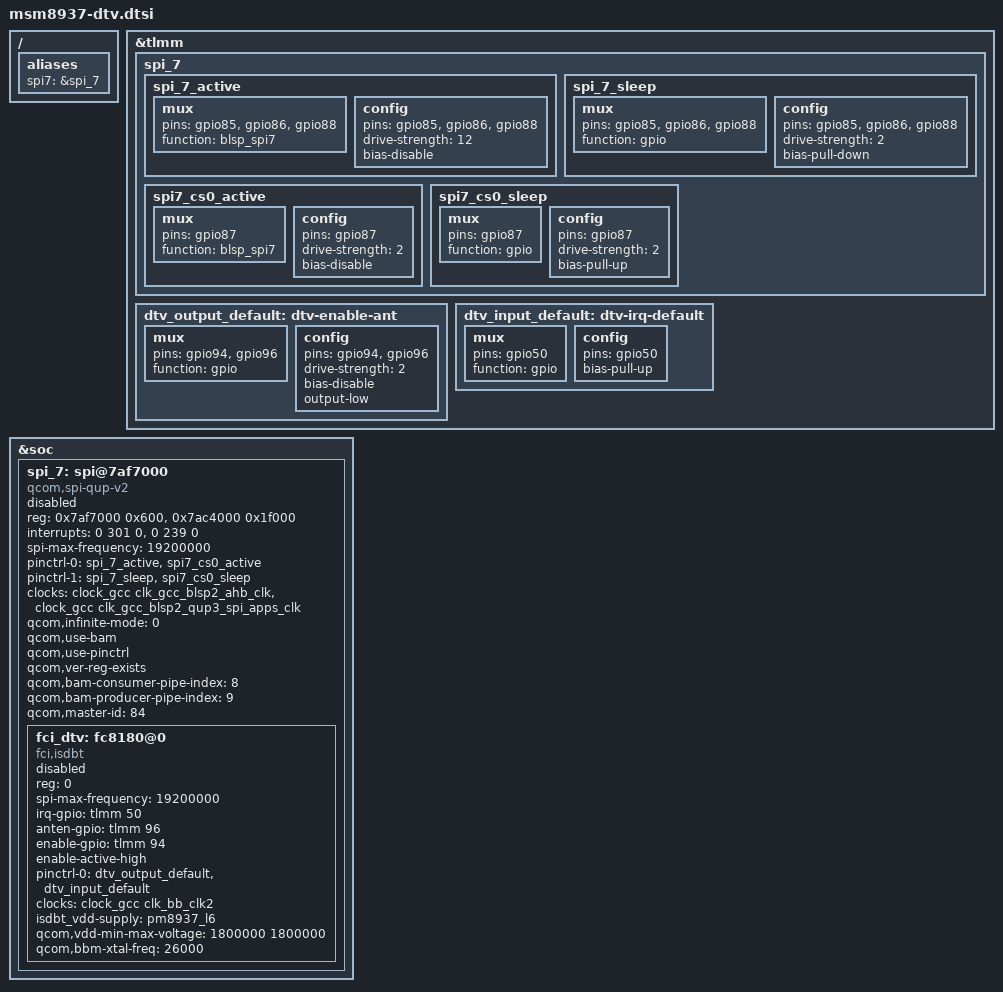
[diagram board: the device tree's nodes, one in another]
&tlmm {
	/delete-node/ spi7;
	spi_7 {
		/* BLSP7 MOSI, MISO, CLK */
		spi_7_active: spi_7_active {
			/* active state */
			mux {
				/* MOSI, MISO, CLK */
				pins = "gpio85", "gpio86", "gpio88";
				function = "blsp_spi7";
			};
			config {
				pins = "gpio85", "gpio86", "gpio88";
				drive-strength = <12>; /* 12 MA */
				bias-disable; /* No PULL */
			};
		};

		spi_7_sleep:spi_7_sleep {
			mux {
				/* MOSI, MISO, CLK */
				pins = "gpio85", "gpio86", "gpio88";
				function = "gpio";
			};
			config {
				pins = "gpio85", "gpio86", "gpio88";
				drive-strength = <2>; /* 2 MA */
				bias-pull-down; /* PULL Down */
			};
		};

		spi7_cs0_active: spi7_cs0_active {
			/* CS */
			mux {
				pins = "gpio87";
				function = "blsp_spi7";
			};
			config {
				pins = "gpio87";
				drive-strength = <2>;
				bias-disable;
			};
		};

		spi7_cs0_sleep: spi7_cs0_sleep {
			/* CS */
			mux {
				pins = "gpio87";
				function = "gpio";
			};
			config {
				pins = "gpio87";
				drive-strength = <2>;
				bias-pull-up;
			};
		};
	};

	/* DTV ldo enable and ant Switch pin */
	dtv_output_default: dtv-enable-ant {
		mux {
			/* enable, reset */
			pins = "gpio94", "gpio96";
			function = "gpio";
		};
		config {
			pins = "gpio94", "gpio96";
			drive-strength = <2>; /* 2 MA */
			bias-disable ; /* No PULL */
			output-low;
		};
	};
	/* DTV interrupt pin */
	dtv_input_default: dtv-irq-default {
			mux {
				pins = "gpio50";
				function = "gpio";
			};
			config {
				pins = "gpio50";
				bias-pull-up; /* pull up */
			};
	};
};

/ {
	aliases {
		spi7 = &spi_7;
    };
};

&soc {
	spi_7: spi@7af7000 { /* BLSP2 QUP2 */
		compatible = "qcom,spi-qup-v2";
		#address-cells = <1>;
		#size-cells = <0>;
		reg-names = "spi_physical", "spi_bam_physical";
		reg = <0x7af7000 0x600>,
		       <0x7ac4000 0x1f000>;
		interrupt-names = "spi_irq", "spi_bam_irq";
		/* IRQ 239 for BLSP2 */
		interrupts = <0 301 0>, <0 239 0>;
		spi-max-frequency = <19200000>;
		pinctrl-names = "spi_default", "spi_sleep";
		pinctrl-0 = <&spi_7_active &spi7_cs0_active>;
		pinctrl-1 = <&spi_7_sleep &spi7_cs0_sleep>;
		clocks = <&clock_gcc clk_gcc_blsp2_ahb_clk>,
			 <&clock_gcc clk_gcc_blsp2_qup3_spi_apps_clk>;
		clock-names = "iface_clk", "core_clk";
		qcom,infinite-mode = <0>;
		qcom,use-bam;
		qcom,use-pinctrl;
		qcom,ver-reg-exists;
		/* need to check pipe index setting*/
		qcom,bam-consumer-pipe-index = <8>;
		qcom,bam-producer-pipe-index = <9>;
		/* master-id for BLSP2 is MSM_BUS_MASTER_BLSP_2 or 84 */
		qcom,master-id = <84>;
		status = "/chosen", "mmi,dtv", "true";

		fci_dtv: fc8180@0 {
			status = "/chosen", "mmi,dtv", "true";
			compatible = "fci,isdbt";
			reg = <0>;
			spi-max-frequency = <19200000>;
			irq-gpio = <&tlmm 50 0>;
			anten-gpio = <&tlmm 96 0>;
			enable-gpio = <&tlmm 94 0>;
			enable-active-high;
			pinctrl-names = "default";
			pinctrl-0 = <&dtv_output_default &dtv_input_default>;
			clocks = <&clock_gcc clk_bb_clk2>;
			clock-names = "dtv_refclk";
			isdbt_vdd-supply = <&pm8937_l6>;
			qcom,vdd-min-max-voltage = <1800000 1800000>;
			qcom,bbm-xtal-freq = <26000>;
		};
	};
};
